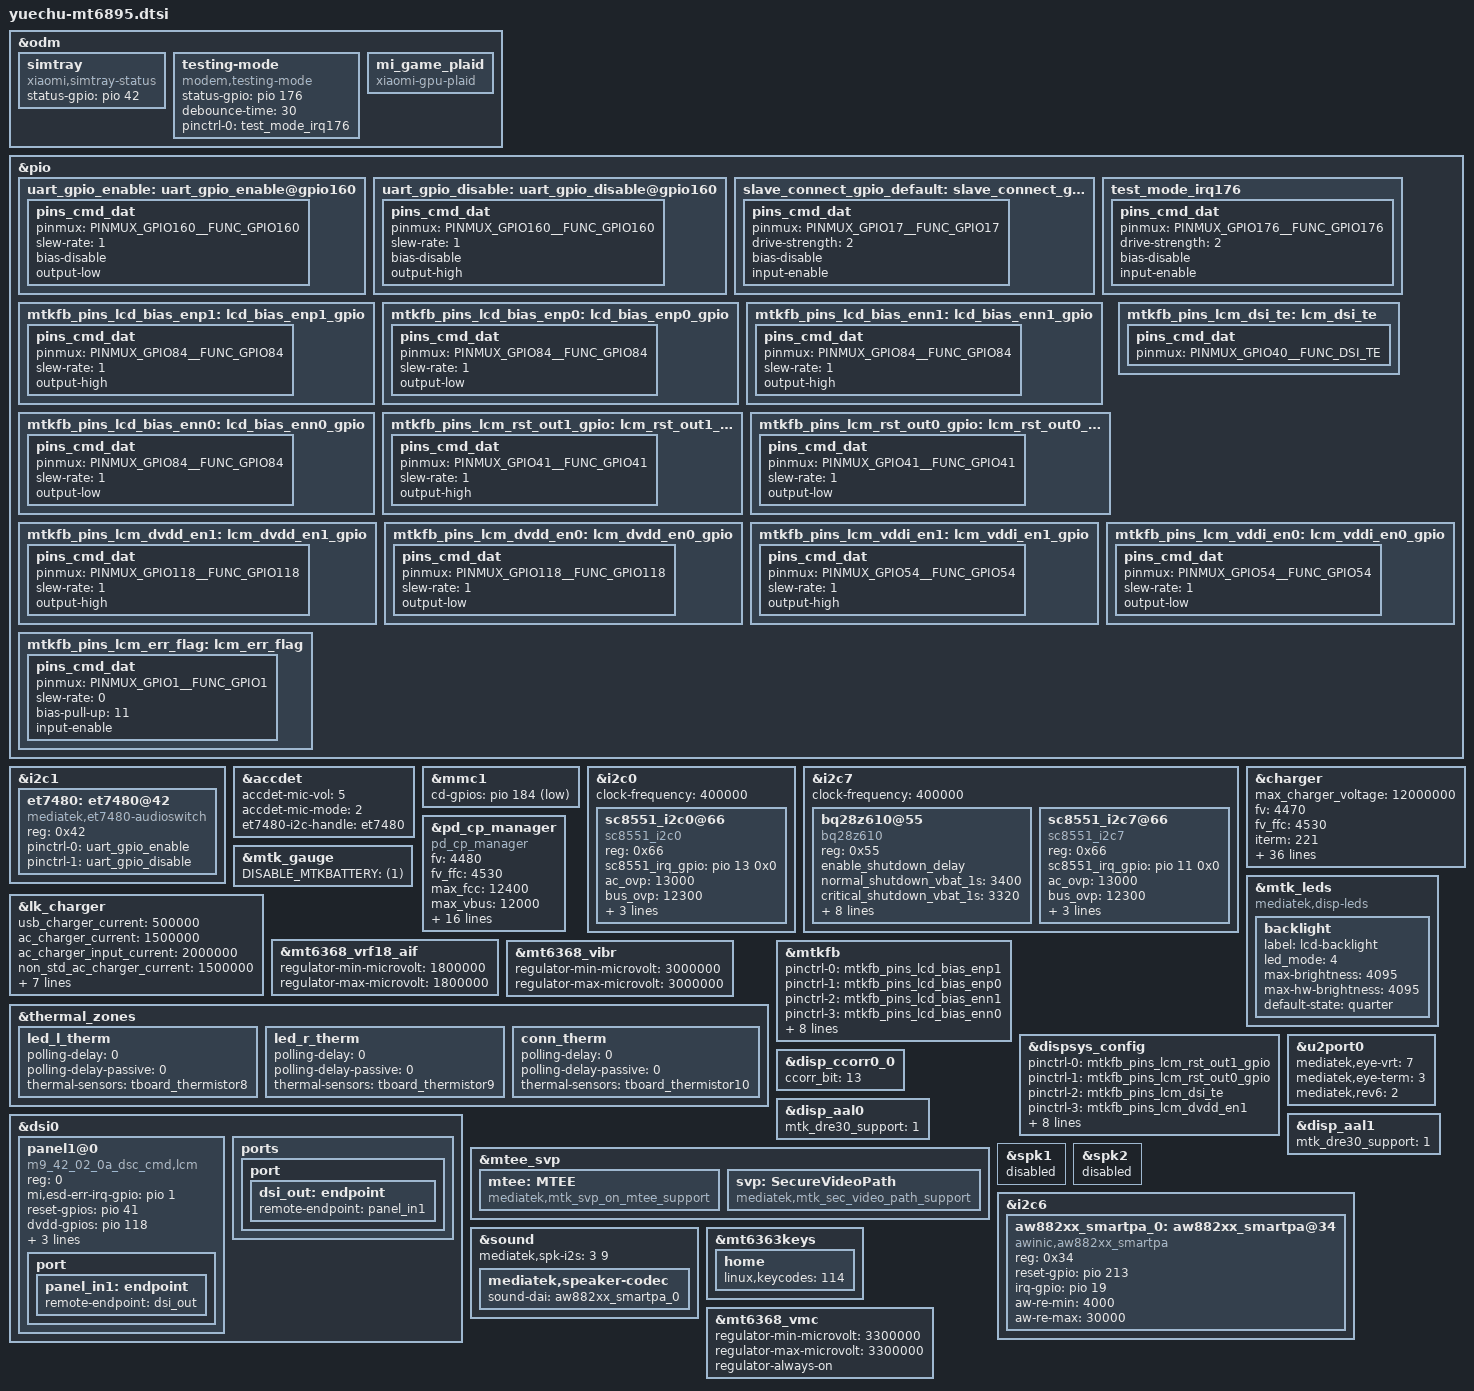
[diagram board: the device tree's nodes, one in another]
/*
this file is only for attribution of yuechu
*/
#include "mediatek/xiaomi-mt6895-common.dtsi"
#include "mediatek/yuechu_mt6895_camera_v4l2.dtsi"
#include "mediatek/xiaomi_yuechu_mt6895_touch.dtsi"
#include "mediatek/yuechu-audio-overlay.dtsi"

&odm {
	simtray {
		compatible = "xiaomi,simtray-status";
		status-gpio =	<&pio 42 0>;
	};
};
/* Audio Switch start */
&pio {
        uart_gpio_enable: uart_gpio_enable@gpio160 {
                pins_cmd_dat {
                        pinmux = <PINMUX_GPIO160__FUNC_GPIO160>;
                        slew-rate = <1>;
                        bias-disable;
                        output-low;
                };
        };

        uart_gpio_disable: uart_gpio_disable@gpio160 {
                pins_cmd_dat {
                        pinmux = <PINMUX_GPIO160__FUNC_GPIO160>;
                        slew-rate = <1>;
                        bias-disable;
                        output-high;
                };
        };
};

&i2c1 {
        et7480: et7480@42 {
                status = "ok";
                compatible = "mediatek,et7480-audioswitch";
                reg = <0x42>;
                pinctrl-names = "uart_enable", "uart_disable";
                pinctrl-0 = <&uart_gpio_enable>;
                pinctrl-1 = <&uart_gpio_disable>;
        };
};

&accdet {
        /* accdet micbias voltage: 0x09:2.85v 0x08:2.8v 0x07,
         * 2.7v;0x05,2.5v;0x02,1.9v
         */
        accdet-mic-vol = <5>;

        /*1:ACC mode, 2:low cost without in bias, 6:low cost with in bias*/
        accdet-mic-mode = <2>;

        et7480-i2c-handle = <&et7480>;
};
/* Audio Swtich end */

&mmc1 {
	cd-gpios = <&pio 184 0x1>;
};

&pio {
        slave_connect_gpio_default: slave_connect_gpio_default@gpio17 {
                pins_cmd_dat {
                        pinmux = <PINMUX_GPIO17__FUNC_GPIO17>;
                        drive-strength = <2>;
                        bias-disable;
                        input-enable;
                };
        };
};

&i2c0 {
	clock-frequency = <400000>;
	status = "okay";
	sc8551_i2c0@66 {
		compatible = "sc8551_i2c0";
		reg = <0x66>;
		sc8551_irq_gpio = <&pio 13 0x0>;
		ac_ovp = <13000>;
		bus_ovp = <12300>;
		bus_ocp = <4500>;
		bat_ovp = <5000>;
		bat_ocp = <8000>;
	};
};

&i2c7 {
	clock-frequency = <400000>;
	status = "okay";
	bq28z610@55 {
		compatible = "bq28z610";
		reg = <0x55>;
		enable_shutdown_delay;
		normal_shutdown_vbat_1s = <3400>;
		critical_shutdown_vbat_1s = <3320>;
		cool_critical_shutdown_vbat = <3300>;
		old_critical_shutdown_vbat = <3310>;
		report_full_rsoc_1s = <9700>;
		soc_gap_1s = <2>;
		slave_connect_gpio = <&pio 17 0x1>;
		pinctrl-names = "default";
		pinctrl-0 = <&slave_connect_gpio_default>;
		soc_decimal_rate = <
			0  38
			10 35
			20 33
			30 33
			40 33
			50 33
			60 33
			70 30
			80 25
			90 20
			95 10 >;
	};
	sc8551_i2c7@66 {
		compatible = "sc8551_i2c7";
		reg = <0x66>;
		sc8551_irq_gpio = <&pio 11 0x0>;
		ac_ovp = <13000>;
		bus_ovp = <12300>;
		bus_ocp = <4500>;
		bat_ovp = <5000>;
		bat_ocp = <8000>;
	};
};

&charger {
		max_charger_voltage = <12000000>;
		fv = <4470>;
		fv_ffc = <4530>;
		iterm = <221>;
		iterm_warm = <221>;
		iterm_ffc = <1238>;
		iterm_ffc_warm = <1547>;
		/* charging current */
		usb_charger_current = <500000>;
		ac_charger_current = <1500000>;
		ac_charger_input_current = <1500000>;
		charging_host_charger_current = <1500000>;
		ffc_low_tbat = <150>;
		ffc_high_tbat = <480>;
		ffc_medium_tbat = <350>;
		ffc_high_soc = <95>;
		step_fallback_hyst = <25>;
		step_forward_hyst = <5>;
		jeita_fallback_hyst = <10>;
		jeita_forward_hyst = <10>;
                mt6368_moscon1_control;
		jeita_fcc_cfg = <(-100)	0	4150	990	650
				1	50	4150	2100	2100
				51	100	4150	2950	2950
				101	150	4150	5120	5120
				151	469	4150	12300	12300
				470	600	4100	2195	2195>;
		jeita_fv_cfg = <(-100)	0	4480
				1	50	4460
				51	100	4480
				101	150	4480
				151	469	4530
				470	600	4090>;
		step_chg_cfg_low_cycle = <3000	3595	12400
					3596	4250	12400
					4251	4300	7880
					4301	4480	6530
					4481	4530	5250>;
		step_chg_cfg_high_cycle = <3000	3595	12400
					3596	4200	12400
					4201	4250	7880
					4251	4480	6530
					4481	4510	5250>;
		thermal_limit_dcp = <1600 1600 1600 1600 1600 1600 1600 1600 1600 1600 1600 1600 1500 1400 1200 1000>;
		thermal_limit_qc2 = <2500 2500 2500 2500 2500 2500 2500 2500 2500 2500 2500 2000 1500 1500 1000 500>;
		thermal_limit_qc3_18w = <2500 2500 2500 2500 2500 2500 2400 2300 2200 2100 1500 1000 800 700 600 500>;
		thermal_limit_qc3_27w = <2500 2500 2500 2500 2500 2500 2400 2300 2200 2100 1500 1000 800 700 600 500>;
		thermal_limit_qc35 = <2500 2500 2500 2500 2500 2500 2400 2300 2200 2100 1500 1000 800 700 600 500>;
		thermal_limit_pd = <12300 9900 8700 7900 6500 5900 5450 4950 4350 2970 2570 2110 1880 1480 490 300>;
};

&mtk_gauge {
        DISABLE_MTKBATTERY = <(1)>;
};

&lk_charger {
		/* charging current */
		usb_charger_current = <500000>;
		ac_charger_current = <1500000>;
		ac_charger_input_current = <2000000>;
		non_std_ac_charger_current = <1500000>;
		charging_host_charger_current = <1500000>;
		ta_ac_charger_current = <1500000>;
		pd_charger_current = <1500000>;

		/* battery temperature protection */
		temp_t4_threshold = <60>;
		temp_t3_threshold = <45>;
		pre_charger_current = <250000>;
		fast_charge_voltage = <3100>;
};

&pd_cp_manager {
		compatible = "pd_cp_manager";
		fv = <4480>;
		fv_ffc = <4530>;
		max_fcc = <12400>;
		max_vbus = <12000>;
		max_ibus = <6200>;
		fcc_low_hyst = <150>;
		fcc_high_hyst = <10>;
		low_tbat = <100>;
		high_tbat = <480>;
		high_vbat = <4400>;
		high_soc = <95>;
		low_fcc = <2000>;
		cv_vbat = <4450>;
		cv_vbat_ffc = <4450>;
		cv_ibat = <2000>;
		cv_ibat_bypass = <1850>;
		vbus_low_gap_div = <400>;
		vbus_high_gap_div = <600>;
		min_pdo_vbus = <8000>;
		max_pdo_vbus = <11000>;
};

&mt6368_vrf18_aif {
	regulator-min-microvolt = <1800000>;
	regulator-max-microvolt = <1800000>;
};

&mt6368_vibr {
	regulator-min-microvolt = <3000000>;
	regulator-max-microvolt = <3000000>;
};

&mtk_leds {
	compatible = "mediatek,disp-leds";
	backlight {
		label = "lcd-backlight";
		led_mode = <4>;
		max-brightness = <4095>;
		max-hw-brightness = <4095>;
		default-state = "quarter";
	};
};

&pio {
	test_mode_irq176: test_mode_irq176 {
                pins_cmd_dat {
			pinmux = <PINMUX_GPIO176__FUNC_GPIO176>;
			drive-strength = <2>;
			bias-disable;
			input-enable;
		};
	};
};

&odm {
	testing-mode {
		compatible = "modem,testing-mode";
		status-gpio = <&pio 176 0>;
		debounce-time = <30>;
		pinctrl-names = "default";
		pinctrl-0 = <&test_mode_irq176 >;
	};
};

&thermal_zones {
		led_l_therm: led_l_therm {
			polling-delay = <0>; /* milliseconds */
			polling-delay-passive = <0>; /* milliseconds */
			thermal-sensors = <&tboard_thermistor8>;
		};
                led_r_therm: led_r_therm {
			polling-delay = <0>; /* milliseconds */
			polling-delay-passive = <0>; /* milliseconds */
			thermal-sensors = <&tboard_thermistor9>;
		};
                conn_therm: conn_therm {
			polling-delay = <0>;
			polling-delay-passive = <0>;
			thermal-sensors = <&tboard_thermistor10>;
		};
};

&odm {
	mi_game_plaid {
		compatible = "xiaomi-gpu-plaid";
	};
};

&pio {
	mtkfb_pins_lcd_bias_enp1: lcd_bias_enp1_gpio {
		pins_cmd_dat {
			pinmux = <PINMUX_GPIO84__FUNC_GPIO84>;
			slew-rate = <1>;
			output-high;
		};
	};

	mtkfb_pins_lcd_bias_enp0: lcd_bias_enp0_gpio {
		pins_cmd_dat {
			pinmux = <PINMUX_GPIO84__FUNC_GPIO84>;
			slew-rate = <1>;
			output-low;
		};
	};

	mtkfb_pins_lcd_bias_enn1: lcd_bias_enn1_gpio {
		pins_cmd_dat {
			pinmux = <PINMUX_GPIO84__FUNC_GPIO84>;
			slew-rate = <1>;
			output-high;
		};
	};

	mtkfb_pins_lcd_bias_enn0: lcd_bias_enn0_gpio {
		pins_cmd_dat {
			pinmux = <PINMUX_GPIO84__FUNC_GPIO84>;
			slew-rate = <1>;
			output-low;
		};
	};

	mtkfb_pins_lcm_rst_out1_gpio: lcm_rst_out1_gpio {
		pins_cmd_dat {
			pinmux = <PINMUX_GPIO41__FUNC_GPIO41>;
			slew-rate = <1>;
			output-high;
		};
	};

	mtkfb_pins_lcm_rst_out0_gpio: lcm_rst_out0_gpio {
		pins_cmd_dat {
			pinmux = <PINMUX_GPIO41__FUNC_GPIO41>;
			slew-rate = <1>;
			output-low;
		};
	};
	mtkfb_pins_lcm_dsi_te: lcm_dsi_te {
		pins_cmd_dat {
			pinmux = <PINMUX_GPIO40__FUNC_DSI_TE>;
		};
	};

	mtkfb_pins_lcm_dvdd_en1: lcm_dvdd_en1_gpio {
		pins_cmd_dat {
			pinmux = <PINMUX_GPIO118__FUNC_GPIO118>;
			slew-rate = <1>;
			output-high;
		};
	};

	mtkfb_pins_lcm_dvdd_en0: lcm_dvdd_en0_gpio {
		pins_cmd_dat {
			pinmux = <PINMUX_GPIO118__FUNC_GPIO118>;
			slew-rate = <1>;
			output-low;
		};
	};

	mtkfb_pins_lcm_vddi_en1:lcm_vddi_en1_gpio{
		pins_cmd_dat{
			pinmux = <PINMUX_GPIO54__FUNC_GPIO54>;
			slew-rate = <1>;
			output-high;
		};
	};

	mtkfb_pins_lcm_vddi_en0:lcm_vddi_en0_gpio{
		pins_cmd_dat{
			pinmux = <PINMUX_GPIO54__FUNC_GPIO54>;
			slew-rate = <1>;
			output-low;
		};
	};

	mtkfb_pins_lcm_err_flag: lcm_err_flag {
		pins_cmd_dat {
			pinmux = <PINMUX_GPIO1__FUNC_GPIO1>;
			slew-rate = <0>;
			bias-pull-up = <11>;
                        input-enable;
		};
	};
};

&mtkfb {
	pinctrl-names = "lcd_bias_enp1_gpio", "lcd_bias_enp0_gpio",
		"lcd_bias_enn1_gpio", "lcd_bias_enn0_gpio",
		"lcm_rst_out1_gpio", "lcm_rst_out0_gpio",
		"mode_te_te", "lcm_dvdd_en1_gpio",
		"lcm_dvdd_en0_gpio", "err_flag_init",
		"lcm_vddi_en1_gpio",
		"lcm_vddi_en0_gpio";
	pinctrl-0 = <&mtkfb_pins_lcd_bias_enp1>;
	pinctrl-1 = <&mtkfb_pins_lcd_bias_enp0>;
	pinctrl-2 = <&mtkfb_pins_lcd_bias_enn1>;
	pinctrl-3 = <&mtkfb_pins_lcd_bias_enn0>;
	pinctrl-4 = <&mtkfb_pins_lcm_rst_out1_gpio>;
	pinctrl-5 = <&mtkfb_pins_lcm_rst_out0_gpio>;
	pinctrl-6 = <&mtkfb_pins_lcm_dsi_te>;
	pinctrl-7 = <&mtkfb_pins_lcm_dvdd_en1>;
	pinctrl-8 = <&mtkfb_pins_lcm_dvdd_en0>;
	pinctrl-9 = <&mtkfb_pins_lcm_err_flag>;
	pinctrl-10 = <&mtkfb_pins_lcm_vddi_en1>;
	pinctrl-11 = <&mtkfb_pins_lcm_vddi_en0>;
	status = "okay";
};
&dispsys_config {
	pinctrl-names =
		"lcm_rst_out1_gpio", "lcm_rst_out0_gpio",
		"mode_te_te", "lcm_dvdd_en1_gpio",
		"lcm_dvdd_en0_gpio", "err_flag_init",
		"lcm_vddi_en1_gpio",
		"lcm_vddi_en0_gpio";
	pinctrl-0 = <&mtkfb_pins_lcm_rst_out1_gpio>;
	pinctrl-1 = <&mtkfb_pins_lcm_rst_out0_gpio>;
	pinctrl-2 = <&mtkfb_pins_lcm_dsi_te>;
	pinctrl-3 = <&mtkfb_pins_lcm_dvdd_en1>;
	pinctrl-4 = <&mtkfb_pins_lcm_dvdd_en0>;
	pinctrl-5 = <&mtkfb_pins_lcm_err_flag>;
	pinctrl-6 = <&mtkfb_pins_lcm_vddi_en1>;
	pinctrl-7 = <&mtkfb_pins_lcm_vddi_en0>;
	status = "okay";

	helper-value = <0>, /*MTK_DRM_OPT_STAGE*/
	<1>, /*MTK_DRM_OPT_USE_CMDQ*/
	<1>, /*MTK_DRM_OPT_USE_M4U*/
	<1>, /*MTK_DRM_OPT_MMQOS_SUPPORT*/
	<1>, /*MTK_DRM_OPT_MMDVFS_SUPPORT*/
	<1>, /*MTK_DRM_OPT_SODI_SUPPORT*/
	<1>, /*MTK_DRM_OPT_IDLE_MGR*/
	<0>, /*MTK_DRM_OPT_IDLEMGR_SWTCH_DECOUPLE*/
	<1>, /*MTK_DRM_OPT_IDLEMGR_BY_REPAINT*/
	<0>, /*MTK_DRM_OPT_IDLEMGR_ENTER_ULPS*/
	<0>, /*MTK_DRM_OPT_IDLEMGR_KEEP_LP11*/
	<1>, /*MTK_DRM_OPT_DYNAMIC_RDMA_GOLDEN_SETTING*/
	<1>, /*MTK_DRM_OPT_IDLEMGR_DISABLE_ROUTINE_IRQ*/
	<0>, /*MTK_DRM_OPT_MET_LOG*/
	<1>, /*MTK_DRM_OPT_USE_PQ*/
	<1>, /*MTK_DRM_OPT_ESD_CHECK_RECOVERY*/
	<0>, /*MTK_DRM_OPT_ESD_CHECK_SWITCH*/
	<1>, /*MTK_DRM_OPT_PRESENT_FENCE*/
	<0>, /*MTK_DRM_OPT_RDMA_UNDERFLOW_AEE*/
	<1>, /*MTK_DRM_OPT_DSI_UNDERRUN_AEE*/
	<1>, /*MTK_DRM_OPT_HRT*/
	<1>, /*MTK_DRM_OPT_HRT_MODE*/
	<0>, /*MTK_DRM_OPT_DELAYED_TRIGGER*/
	<1>, /*MTK_DRM_OPT_OVL_EXT_LAYER*/
	<1>, /*MTK_DRM_OPT_AOD*/
	<1>, /*MTK_DRM_OPT_RPO*/
	<0>, /*MTK_DRM_OPT_DUAL_PIPE*/
	<0>, /*MTK_DRM_OPT_DC_BY_HRT*/
	<1>, /*MTK_DRM_OPT_OVL_WCG*/
	<0>, /*MTK_DRM_OPT_OVL_SBCH*/
	<1>, /*MTK_DRM_OPT_COMMIT_NO_WAIT_VBLANK*/
	<0>, /*MTK_DRM_OPT_MET*/
	<0>, /*MTK_DRM_OPT_REG_PARSER_RAW_DUMP*/
	<0>, /*MTK_DRM_OPT_VP_PQ*/
	<0>, /*MTK_DRM_OPT_GAME_PQ*/
	<0>, /*MTK_DRM_OPT_MMPATH*/
	<0>, /*MTK_DRM_OPT_HBM*/
	<0>, /*MTK_DRM_OPT_VDS_PATH_SWITCH*/
	<0>, /*MTK_DRM_OPT_LAYER_REC*/
	<0>, /*MTK_DRM_OPT_CLEAR_LAYER*/
	<1>, /*MTK_DRM_OPT_LFR*/
	<0>, /*MTK_DRM_OPT_SF_PF*/
	<1>, /*MTK_DRM_OPT_DYN_MIPI_CHANGE*/
	<1>, /*MTK_DRM_OPT_PRIM_DUAL_PIPE*/
	<1>, /*MTK_DRM_OPT_MSYNC2_0*/
	<1>, /*MTK_DRM_OPT_MML_PRIMARY*/
	<0>, /*MTK_DRM_OPT_DUAL_TE*/
	<1>, /*MTK_DRM_OPT_VIRTUAL_DISP*/
	<1>; /*MTK_DRM_OPT_RES_SWITCH*/
};

&dsi0 {
	status = "okay";
	#address-cells = <1>;
	#size-cells = <0>;
	panel1@0 {
		compatible = "m9_42_02_0a_dsc_cmd,lcm";
		reg = <0>;
		mi,esd-err-irq-gpio = <&pio 1 0x2002>;
		reset-gpios = <&pio 41 0>;
		dvdd-gpios = <&pio 118 0>;
		vibr-supply = <&mt6368_vibr>;
		vrf18-supply = <&mt6368_vrf18_aif>;
		vddi-gpios = <&pio 54 0>;
		pinctrl-names = "default";
		port {
			panel_in1: endpoint {
				remote-endpoint = <&dsi_out>;
			};
		};
	};
	ports {
		port {
			dsi_out: endpoint {
				remote-endpoint = <&panel_in1>;
			};
		};
	};
};

&u2port0{
		mediatek,eye-vrt = <7>;
		mediatek,eye-term = <3>;
		mediatek,rev6 = <2>;
};

&disp_ccorr0_0 {
	ccorr_bit = <13>;
};

&disp_aal0 {
	mtk_dre30_support = <1>;
};
&disp_aal1 {
	mtk_dre30_support = <1>;
};

&mtee_svp {
	mtee: MTEE {
                   compatible = "mediatek,mtk_svp_on_mtee_support";
	};

	svp: SecureVideoPath {
                   compatible = "mediatek,mtk_sec_video_path_support";
	};
};

&spk1 {
	status = "disabled";
};

&spk2 {
	status = "disabled";
};

&i2c6 {
	status = "okay";
	/* BOT Smart PA */
	aw882xx_smartpa_0: aw882xx_smartpa@34 {
		compatible = "awinic,aw882xx_smartpa";
		#sound-dai-cells = <0>;
		reg = <0x34>;
		reset-gpio = <&pio 213 0>;
		irq-gpio = <&pio 19 0x0>;
		aw-re-min = <4000>;
		aw-re-max= <30000>;
		/*aw-cali-mode = "none";*/
		status = "okay";
	};
};

&sound {
	mediatek,spk-i2s = <3 9>;
	mediatek,speaker-codec {
		sound-dai = <&aw882xx_smartpa_0>;
	};
};

&mt6363keys {
	home {
		linux,keycodes = <114>;
	};
};

&mt6368_vmc {
	regulator-min-microvolt = <3300000>;
	regulator-max-microvolt = <3300000>;
	regulator-always-on;
};
